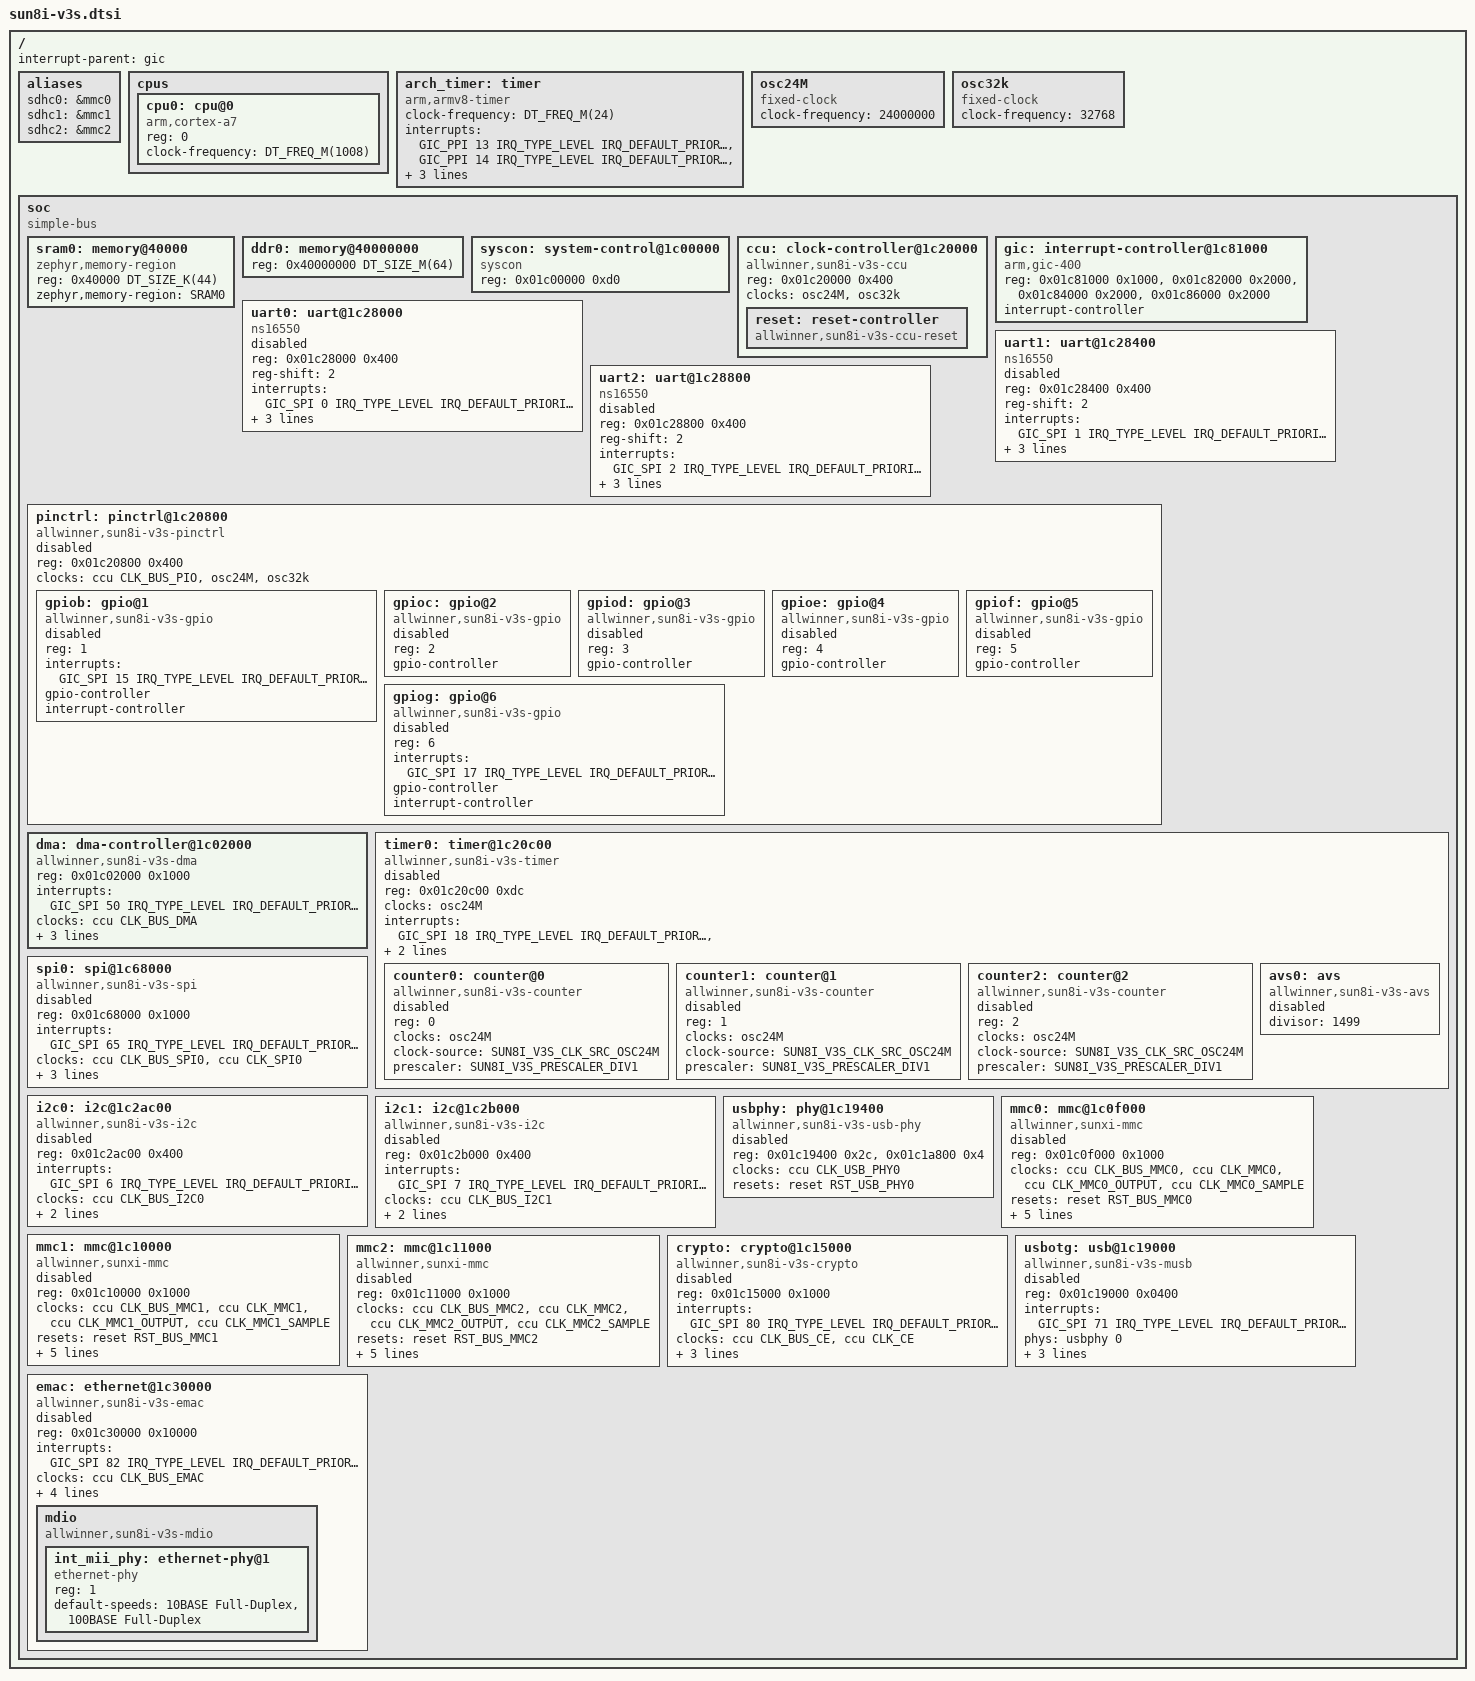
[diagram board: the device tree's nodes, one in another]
/*
 * Copyright (c) 2026 jeck chen <baidxi404629@gmail.com>
 *
 * SPDX-License-Identifier: Apache-2.0
 */

#include <mem.h>
#include <freq.h>

#include <arm/armv7-a.dtsi>
#include <zephyr/dt-bindings/interrupt-controller/arm-gic.h>
#include <zephyr/dt-bindings/clock/allwinner,sun8i-v3s-ccu.h>
#include <zephyr/dt-bindings/reset/allwinner,sun8i-v3s-ccu.h>
#include <zephyr/dt-bindings/counter/sun8i-v3s-counter.h>
#include <zephyr/dt-bindings/dma/allwinner,sun8i-v3s-dma.h>

/ {
	interrupt-parent = <&gic>;
	#address-cells = <1>;
	#size-cells = <1>;

	aliases {
		sdhc0 = &mmc0;
		sdhc1 = &mmc1;
		sdhc2 = &mmc2;
	};

	cpus {
		#address-cells = <1>;
		#size-cells = <0>;

		cpu0: cpu@0 {
			compatible = "arm,cortex-a7";
			device_type = "cpu";
			reg = <0>;
			clock-frequency = <DT_FREQ_M(1008)>;
		};
	};

	arch_timer: timer {
		compatible = "arm,armv8-timer";
		clock-frequency = <DT_FREQ_M(24)>;
		status = "okay";
		interrupts = <GIC_PPI 13 IRQ_TYPE_LEVEL IRQ_DEFAULT_PRIORITY>,
			     <GIC_PPI 14 IRQ_TYPE_LEVEL IRQ_DEFAULT_PRIORITY>,
			     <GIC_PPI 11 IRQ_TYPE_LEVEL IRQ_DEFAULT_PRIORITY>,
			     <GIC_PPI 10 IRQ_TYPE_LEVEL IRQ_DEFAULT_PRIORITY>;
		interrupt-parent = <&gic>;
	};

	/* Oscillator clocks */
	osc24M: osc24M {
		compatible = "fixed-clock";
		clock-frequency = <24000000>;
		#clock-cells = <0>;
		#clock-source-cells = <0>;
	};

	osc32k: osc32k {
		compatible = "fixed-clock";
		clock-frequency = <32768>;
		#clock-cells = <0>;
	};

	soc {
		compatible = "simple-bus";
		#address-cells = <1>;
		#size-cells = <1>;
		ranges;
	
		sram0: memory@40000 {
			device_type = "memory";
			compatible = "zephyr,memory-region", "mmio-sram";
			reg = <0x40000 DT_SIZE_K(44)>;
			zephyr,memory-region = "SRAM0";
		};

		ddr0: memory@40000000 {
			device_type = "memory";
			reg = <0x40000000 DT_SIZE_M(64)>;
		};

		syscon: system-control@1c00000 {
			compatible = "syscon";
			reg = <0x01c00000 0xd0>;
			status = "okay";
		};

		ccu: clock-controller@1c20000 {
			compatible = "allwinner,sun8i-v3s-ccu";
			status = "okay";
			reg = <0x01c20000 0x400>;
			clocks = <&osc24M>, <&osc32k>;
			clock-names = "hosc", "losc";
			#clock-cells = <1>;
			#reset-cells = <1>;
			reset: reset-controller {
				compatible = "allwinner,sun8i-v3s-ccu-reset";
				#reset-cells = <1>;
				status = "okay";
			};
		};

		gic: interrupt-controller@1c81000 {
			compatible = "arm,gic-400", "arm,gic-v2", "arm,gic";
			status = "okay";
			reg = <0x01c81000 0x1000>,
			      <0x01c82000 0x2000>,
			      <0x01c84000 0x2000>,
			      <0x01c86000 0x2000>;
			interrupt-controller;
			#interrupt-cells = <4>;
			#address-cells = <0>;
		};

		uart0: uart@1c28000 {
			compatible = "ns16550", "snps,dw-apb-uart";
			reg = <0x01c28000 0x400>;
			reg-shift = <2>;
			interrupts = <GIC_SPI 0 IRQ_TYPE_LEVEL
				      IRQ_DEFAULT_PRIORITY>;
			clock-frequency = <DT_FREQ_M(24)>;
			dmas = <&dma SUN8I_V3S_DMA_DRQ_UART0>,
			       <&dma SUN8I_V3S_DMA_DRQ_UART0>;
			dma-names = "tx", "rx";
			status = "disabled";
		};

		uart1: uart@1c28400 {
			compatible = "ns16550", "snps,dw-apb-uart";
			reg = <0x01c28400 0x400>;
			reg-shift = <2>;
			interrupts = <GIC_SPI 1 IRQ_TYPE_LEVEL
				      IRQ_DEFAULT_PRIORITY>;
			clock-frequency = <DT_FREQ_M(24)>;
			dmas = <&dma SUN8I_V3S_DMA_DRQ_UART1>,
			       <&dma SUN8I_V3S_DMA_DRQ_UART1>;
			dma-names = "tx", "rx";
			status = "disabled";
		};

		uart2: uart@1c28800 {
			compatible = "ns16550", "snps,dw-apb-uart";
			reg = <0x01c28800 0x400>;
			reg-shift = <2>;
			interrupts = <GIC_SPI 2 IRQ_TYPE_LEVEL
				      IRQ_DEFAULT_PRIORITY>;
			clock-frequency = <DT_FREQ_M(24)>;
			dmas = <&dma SUN8I_V3S_DMA_DRQ_UART2>,
			       <&dma SUN8I_V3S_DMA_DRQ_UART2>;
			dma-names = "tx", "rx";
			status = "disabled";
		};

		pinctrl: pinctrl@1c20800 {
			compatible = "allwinner,sun8i-v3s-pinctrl";
			reg = <0x01c20800 0x400>;
			clocks = <&ccu CLK_BUS_PIO>,<&osc24M>, <&osc32k>;
			clock-names = "bus","hosc","losc";
			#address-cells = <1>;
			#size-cells = <0>;
			status = "disabled";
			gpiob: gpio@1 {
				compatible = "allwinner,sun8i-v3s-gpio";
				reg = <1>;
				interrupts = <GIC_SPI 15 IRQ_TYPE_LEVEL IRQ_DEFAULT_PRIORITY>;
				gpio-controller;
				#gpio-cells = <2>;
				interrupt-controller;
				#interrupt-cells = <2>;
				status = "disabled";
			};
			gpioc: gpio@2 {
				compatible = "allwinner,sun8i-v3s-gpio";
				reg = <2>;
				gpio-controller;
				#gpio-cells = <2>;
				status = "disabled";
			};
			gpiod: gpio@3 {
				compatible = "allwinner,sun8i-v3s-gpio";
				reg = <3>;
				gpio-controller;
				#gpio-cells = <2>;
				status = "disabled";	
			};
			gpioe: gpio@4 {
				compatible = "allwinner,sun8i-v3s-gpio";
				reg = <4>;
				gpio-controller;
				#gpio-cells = <2>;
				status = "disabled";
			};
			gpiof: gpio@5 {
				compatible = "allwinner,sun8i-v3s-gpio";
				reg = <5>;
				gpio-controller;
				#gpio-cells = <2>;
				status = "disabled";
			};
			gpiog: gpio@6 {
				compatible = "allwinner,sun8i-v3s-gpio";
				reg = <6>;
				interrupts = <GIC_SPI 17 IRQ_TYPE_LEVEL IRQ_DEFAULT_PRIORITY>;
				gpio-controller;
				#gpio-cells = <2>;
				interrupt-controller;
				#interrupt-cells = <2>;
				status = "disabled";
			};
		};

		dma: dma-controller@1c02000 {
			compatible = "allwinner,sun8i-v3s-dma";
			reg = <0x01c02000 0x1000>;
			interrupts = <GIC_SPI 50 IRQ_TYPE_LEVEL
						IRQ_DEFAULT_PRIORITY>;
			clocks = <&ccu CLK_BUS_DMA>;
			resets = <&reset RST_BUS_DMA>;
			#dma-cells = <1>;
			dma-channels = <8>;
			dma-requests = <24>;
			status = "okay";
		};

		timer0: timer@1c20c00 {
			compatible = "allwinner,sun8i-v3s-timer";
			reg = <0x01c20c00 0xdc>;
			clocks = <&osc24M>;
			#address-cells = <1>;
			#size-cells = <0>;
			interrupts = <GIC_SPI 18 IRQ_TYPE_LEVEL IRQ_DEFAULT_PRIORITY>,
				     <GIC_SPI 19 IRQ_TYPE_LEVEL IRQ_DEFAULT_PRIORITY>,
				     <GIC_SPI 20 IRQ_TYPE_LEVEL IRQ_DEFAULT_PRIORITY>;
			status = "disabled";

			counter0: counter@0 {
				compatible = "allwinner,sun8i-v3s-counter";
				reg = <0>;
				clocks = <&osc24M>;
				clock-source = <SUN8I_V3S_CLK_SRC_OSC24M>;
				prescaler = <SUN8I_V3S_PRESCALER_DIV1>;
				status = "disabled";
			};

			counter1: counter@1 {
				compatible = "allwinner,sun8i-v3s-counter";
				reg = <1>;
				clocks = <&osc24M>;
				clock-source = <SUN8I_V3S_CLK_SRC_OSC24M>;
				prescaler = <SUN8I_V3S_PRESCALER_DIV1>;
				status = "disabled";
			};

			counter2: counter@2 {
				compatible = "allwinner,sun8i-v3s-counter";
				reg = <2>;
				clocks = <&osc24M>;
				clock-source = <SUN8I_V3S_CLK_SRC_OSC24M>;
				prescaler = <SUN8I_V3S_PRESCALER_DIV1>;
				status = "disabled";
			};

			avs0: avs {
				compatible = "allwinner,sun8i-v3s-avs";
				divisor = <1499>;
				status = "disabled";
			};
		};

		spi0: spi@1c68000 {
			compatible = "allwinner,sun8i-v3s-spi";
			reg = <0x01c68000 0x1000>;
			interrupts = <GIC_SPI 65 IRQ_TYPE_LEVEL IRQ_DEFAULT_PRIORITY>;
			clocks = <&ccu CLK_BUS_SPI0>, <&ccu CLK_SPI0>;
			clock-names = "bus", "mod";
			resets = <&reset RST_BUS_SPI0>;
			clock-frequency = <DT_FREQ_M(24)>;
			dmas = <&dma 23>, <&dma 23>;
			dma-names = "tx", "rx";
			#address-cells = <1>;
			#size-cells = <0>;
			status = "disabled";
		};

		i2c0: i2c@1c2ac00 {
			compatible = "allwinner,sun8i-v3s-i2c";
			reg = <0x01c2ac00 0x400>;
			interrupts = <GIC_SPI 6 IRQ_TYPE_LEVEL IRQ_DEFAULT_PRIORITY>;
			clocks = <&ccu CLK_BUS_I2C0>;
			clock-names = "bus";
			resets = <&reset RST_BUS_I2C0>;
			clock-frequency = <100000>;
			#address-cells = <1>;
			#size-cells = <0>;
			status = "disabled";
		};

		i2c1: i2c@1c2b000 {
			compatible = "allwinner,sun8i-v3s-i2c";
			reg = <0x01c2b000 0x400>;
			interrupts = <GIC_SPI 7 IRQ_TYPE_LEVEL IRQ_DEFAULT_PRIORITY>;
			clocks = <&ccu CLK_BUS_I2C1>;
			clock-names = "bus";
			resets = <&reset RST_BUS_I2C1>;
			clock-frequency = <100000>;
			#address-cells = <1>;
			#size-cells = <0>;
			status = "disabled";
		};

		usbphy: phy@1c19400 {
			compatible = "allwinner,sun8i-v3s-usb-phy", "allwinner,sun4i-usb-phy";
			reg = <0x01c19400 0x2c>, <0x01c1a800 0x4>;
			reg-names = "phy_ctrl", "pmu0";
			clocks = <&ccu CLK_USB_PHY0>;
			clock-names = "usb0_phy";
			resets = <&reset RST_USB_PHY0>;
			reset-names = "usb0_reset";
			#phy-cells = <1>;
			status = "disabled";
		};

		mmc0: mmc@1c0f000 {
			compatible = "allwinner,sunxi-mmc";
			reg = <0x01c0f000 0x1000>;
			clocks = <&ccu CLK_BUS_MMC0>, <&ccu CLK_MMC0>,
				 <&ccu CLK_MMC0_OUTPUT>, <&ccu CLK_MMC0_SAMPLE>;
			clock-names = "ahb", "mmc", "output", "sample";
			resets = <&reset RST_BUS_MMC0>;
			reset-names = "ahb";
			interrupts = <GIC_SPI 60 IRQ_TYPE_LEVEL IRQ_DEFAULT_PRIORITY>;
			bus-width = <4>;
			max-bus-freq = <50000000>;
			min-bus-freq = <400000>;
			status = "disabled";
		};

		mmc1: mmc@1c10000 {
			compatible = "allwinner,sunxi-mmc";
			reg = <0x01c10000 0x1000>;
			clocks = <&ccu CLK_BUS_MMC1>, <&ccu CLK_MMC1>,
				 <&ccu CLK_MMC1_OUTPUT>, <&ccu CLK_MMC1_SAMPLE>;
			clock-names = "ahb", "mmc", "output", "sample";
			resets = <&reset RST_BUS_MMC1>;
			reset-names = "ahb";
			interrupts = <GIC_SPI 61 IRQ_TYPE_LEVEL IRQ_DEFAULT_PRIORITY>;
			bus-width = <4>;
			max-bus-freq = <50000000>;
			min-bus-freq = <400000>;
			status = "disabled";
		};

		mmc2: mmc@1c11000 {
			compatible = "allwinner,sunxi-mmc";
			reg = <0x01c11000 0x1000>;
			clocks = <&ccu CLK_BUS_MMC2>, <&ccu CLK_MMC2>,
				 <&ccu CLK_MMC2_OUTPUT>, <&ccu CLK_MMC2_SAMPLE>;
			clock-names = "ahb", "mmc", "output", "sample";
			resets = <&reset RST_BUS_MMC2>;
			reset-names = "ahb";
			interrupts = <GIC_SPI 62 IRQ_TYPE_LEVEL IRQ_DEFAULT_PRIORITY>;
			bus-width = <1>;
			max-bus-freq = <50000000>;
			min-bus-freq = <400000>;
			status = "disabled";
		};

		crypto: crypto@1c15000 {
			compatible = "allwinner,sun8i-v3s-crypto";
			reg = <0x01c15000 0x1000>;
			interrupts = <GIC_SPI 80 IRQ_TYPE_LEVEL IRQ_DEFAULT_PRIORITY>;
			clocks = <&ccu CLK_BUS_CE>, <&ccu CLK_CE>;
			clock-names = "ahb", "mod";
			resets = <&reset RST_BUS_CE>;
			reset-names = "ahb";
			dmas = <&dma SUN8I_V3S_DMA_DRQ_CE>,
			       <&dma SUN8I_V3S_DMA_DRQ_CE>;
			dma-names = "rx", "tx";
			status = "disabled";
		};

		usbotg: usb@1c19000 {
			compatible = "allwinner,sun8i-v3s-musb";
			reg = <0x01c19000 0x0400>;
			interrupts = <GIC_SPI 71 IRQ_TYPE_LEVEL IRQ_DEFAULT_PRIORITY>;
			phys = <&usbphy 0>;
			clocks = <&ccu CLK_BUS_OTG>;
			resets = <&reset RST_BUS_OTG>;
			num-bidir-endpoints = <5>;
			status = "disabled";
		};

		emac: ethernet@1c30000 {
			compatible = "allwinner,sun8i-v3s-emac";
			reg = <0x01c30000 0x10000>;
			interrupts = <GIC_SPI 82 IRQ_TYPE_LEVEL IRQ_DEFAULT_PRIORITY>;
			clocks = <&ccu CLK_BUS_EMAC>;
			resets = <&reset RST_BUS_EMAC>;
			allwinner,phy-addr = <1>;
			phy-handle = <&int_mii_phy>;
			phy-connection-type = "mii";
			status = "disabled";

			mdio: mdio {
				compatible = "allwinner,sun8i-v3s-mdio";
				#address-cells = <1>;
				#size-cells = <0>;

				int_mii_phy: ethernet-phy@1 {
						compatible = "ethernet-phy";
						reg = <1>;
						default-speeds = "10BASE Full-Duplex",
								 "100BASE Full-Duplex";
					};
			};
		};
	};
};
